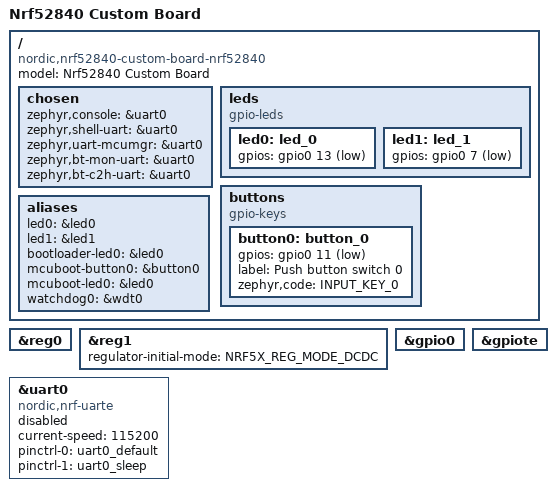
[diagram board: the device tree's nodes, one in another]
/*
 * Copyright (c) 2017 Linaro Limited
 *
 * SPDX-License-Identifier: Apache-2.0
 */

/dts-v1/;
#include <nordic/nrf52840_qiaa.dtsi>
#include <nordic/nrf52840_partition.dtsi>
#include "nrf52840_custom_board_nrf52840-pinctrl.dtsi"
#include <zephyr/dt-bindings/input/input-event-codes.h>

/ {
	model = "Nrf52840 Custom Board";
	compatible = "nordic,nrf52840-custom-board-nrf52840";

	chosen {
		zephyr,console = &uart0;
		zephyr,shell-uart = &uart0;
		zephyr,uart-mcumgr = &uart0;
		zephyr,bt-mon-uart = &uart0;
		zephyr,bt-c2h-uart = &uart0;
	};

	leds {
		compatible = "gpio-leds";
		led0: led_0 {
			gpios = <&gpio0 13 GPIO_ACTIVE_LOW>;
		};
		led1: led_1 {
			gpios = <&gpio0 7 GPIO_ACTIVE_LOW>;
		};
	};

	buttons {
		compatible = "gpio-keys";
		button0: button_0 {
			gpios = <&gpio0 11 (GPIO_PULL_UP | GPIO_ACTIVE_LOW)>;
			label = "Push button switch 0";
			zephyr,code = <INPUT_KEY_0>;
		};
	};

	/* These aliases are provided for compatibility with samples */
	aliases {
		led0 = &led0;
		led1 = &led1;
		bootloader-led0 = &led0;
		mcuboot-button0 = &button0;
		mcuboot-led0 = &led0;
		watchdog0 = &wdt0;
	};
};

&reg0 {
	status = "okay";
};

&reg1 {
	regulator-initial-mode = <NRF5X_REG_MODE_DCDC>;
};

&gpio0 {
	status = "okay";
};

&uart0 {
	compatible = "nordic,nrf-uarte";
	status = "disabled";
	current-speed = <115200>;
	pinctrl-0 = <&uart0_default>;
	pinctrl-1 = <&uart0_sleep>;
	pinctrl-names = "default", "sleep";
};

&gpiote {
	status = "okay";
};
